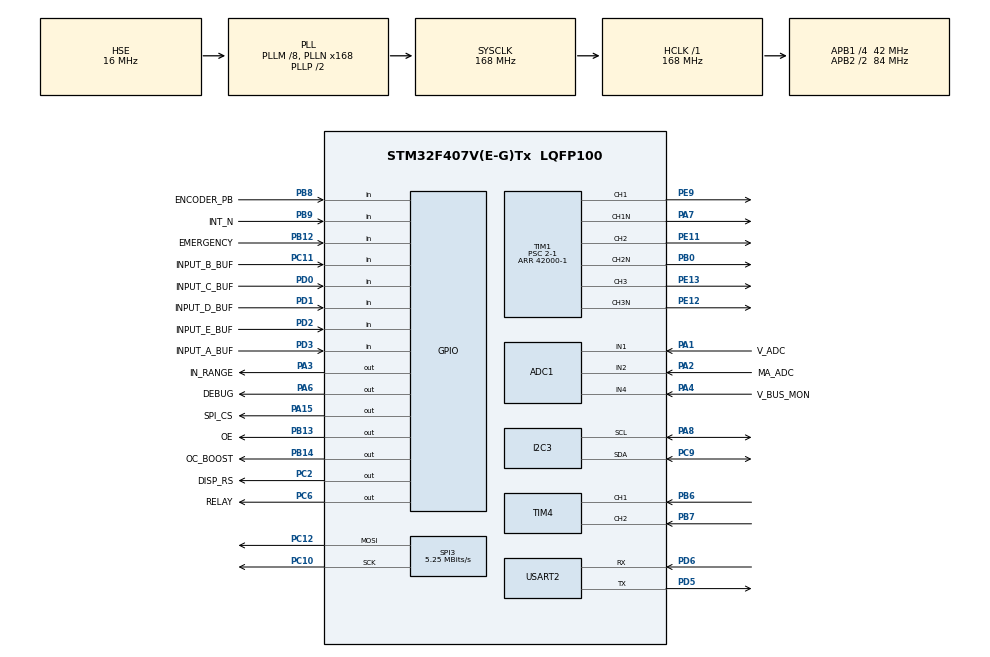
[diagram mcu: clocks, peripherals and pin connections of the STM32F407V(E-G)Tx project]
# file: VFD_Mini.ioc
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ADC1.Channel-0\#ChannelRegularConversion=ADC_CHANNEL_1
ADC1.Channel-1\#ChannelRegularConversion=ADC_CHANNEL_2
ADC1.Channel-2\#ChannelRegularConversion=ADC_CHANNEL_VREFINT
ADC1.Channel-3\#ChannelRegularConversion=ADC_CHANNEL_4
ADC1.ClockPrescaler=ADC_CLOCK_SYNC_PCLK_DIV8
ADC1.ContinuousConvMode=DISABLE
ADC1.DMAContinuousRequests=ENABLE
ADC1.EOCSelection=ADC_EOC_SEQ_CONV
ADC1.ExternalTrigConv=ADC_EXTERNALTRIGCONV_T2_TRGO
ADC1.InjNumberOfConversion=0
ADC1.NbrOfConversion=4
ADC1.NbrOfConversionFlag=1
ADC1.Rank-0\#ChannelRegularConversion=1
ADC1.Rank-1\#ChannelRegularConversion=2
ADC1.Rank-2\#ChannelRegularConversion=3
ADC1.Rank-3\#ChannelRegularConversion=4
ADC1.SamplingTime-0\#ChannelRegularConversion=ADC_SAMPLETIME_28CYCLES
ADC1.SamplingTime-1\#ChannelRegularConversion=ADC_SAMPLETIME_28CYCLES
ADC1.SamplingTime-2\#ChannelRegularConversion=ADC_SAMPLETIME_28CYCLES
ADC1.SamplingTime-3\#ChannelRegularConversion=ADC_SAMPLETIME_28CYCLES
ADC1.master=1
Dma.ADC1.0.Direction=DMA_PERIPH_TO_MEMORY
Dma.ADC1.0.FIFOMode=DMA_FIFOMODE_DISABLE
Dma.ADC1.0.Instance=DMA2_Stream0
Dma.ADC1.0.MemDataAlignment=DMA_MDATAALIGN_HALFWORD
Dma.ADC1.0.MemInc=DMA_MINC_ENABLE
Dma.ADC1.0.Mode=DMA_CIRCULAR
Dma.ADC1.0.PeriphDataAlignment=DMA_PDATAALIGN_HALFWORD
Dma.ADC1.0.PeriphInc=DMA_PINC_DISABLE
Dma.ADC1.0.Priority=DMA_PRIORITY_LOW
Dma.Request0=ADC1
I2C3.I2C_Mode=I2C_Fast
IWDG.Prescaler=IWDG_PRESCALER_64
IWDG.Reload=499
Mcu.Family=STM32F4
Mcu.Name=STM32F407V(E-G)Tx
Mcu.Package=LQFP100
NVIC.ADC_IRQn=true\:0\:0\:false\:false\:true\:true\:true\:true
NVIC.DMA2_Stream0_IRQn=true\:0\:0\:false\:false\:true\:false\:true\:true
NVIC.PriorityGroup=NVIC_PRIORITYGROUP_4
NVIC.TIM8_TRG_COM_TIM14_IRQn=true\:0\:0\:false\:false\:true\:true\:true\:true
PA1.GPIO_Label=V_ADC
PA1.Signal=ADCx_IN1
PA13.Mode=Trace_Asynchronous_SW
PA13.Signal=SYS_JTMS-SWDIO
PA14.Mode=Trace_Asynchronous_SW
PA14.Signal=SYS_JTCK-SWCLK
PA15.GPIO_Label=SPI_CS
PA15.Signal=GPIO_Output
PA2.GPIO_Label=MA_ADC
PA2.Signal=ADCx_IN2
PA3.GPIO_Label=IN_RANGE
PA3.Signal=GPIO_Output
PA4.GPIO_Label=V_BUS_MON
PA4.Signal=ADCx_IN4
PA6.GPIO_Label=DEBUG
PA6.Signal=GPIO_Output
PA7.Mode=PWM Generation1 CH1 CH1N
PA7.Signal=TIM1_CH1N
PA8.Mode=I2C
PA8.Signal=I2C3_SCL
PB0.Mode=PWM Generation2 CH2 CH2N
PB0.Signal=TIM1_CH2N
PB12.GPIO_Label=EMERGENCY
PB12.Signal=GPIO_Input
PB13.GPIO_Label=OE
PB13.Signal=GPIO_Output
PB14.GPIO_Label=OC_BOOST
PB14.Signal=GPIO_Output
PB3.Mode=Trace_Asynchronous_SW
PB3.Signal=SYS_JTDO-SWO
PB6.Signal=S_TIM4_CH1
PB7.Signal=S_TIM4_CH2
PB8.GPIO_Label=ENCODER_PB
PB8.Signal=GPIO_Input
PB9.GPIO_Label=INT_N
PB9.Signal=GPIO_Input
PC10.Mode=TX_Only_Simplex_Unidirect_Master
PC10.Signal=SPI3_SCK
PC11.GPIO_Label=INPUT_B_BUF
PC11.Signal=GPIO_Input
PC12.Mode=TX_Only_Simplex_Unidirect_Master
PC12.Signal=SPI3_MOSI
PC2.GPIO_Label=DISP_RS
PC2.Signal=GPIO_Output
PC6.GPIO_Label=RELAY
PC6.Signal=GPIO_Output
PC9.Mode=I2C
PC9.Signal=I2C3_SDA
PD0.GPIO_Label=INPUT_C_BUF
PD0.Signal=GPIO_Input
PD1.GPIO_Label=INPUT_D_BUF
PD1.Signal=GPIO_Input
PD2.GPIO_Label=INPUT_E_BUF
PD2.Signal=GPIO_Input
PD3.GPIO_Label=INPUT_A_BUF
PD3.Signal=GPIO_Input
PD5.Mode=Asynchronous
PD5.Signal=USART2_TX
PD6.Mode=Asynchronous
PD6.Signal=USART2_RX
PE11.Signal=S_TIM1_CH2
PE12.Mode=PWM Generation3 CH3 CH3N
PE12.Signal=TIM1_CH3N
PE13.Signal=S_TIM1_CH3
PE9.Signal=S_TIM1_CH1
PH0-OSC_IN.Mode=HSE-External-Oscillator
PH0-OSC_IN.Signal=RCC_OSC_IN
PH1-OSC_OUT.Mode=HSE-External-Oscillator
PH1-OSC_OUT.Signal=RCC_OSC_OUT
ProjectManager.HeapSize=0x200
ProjectManager.StackSize=0x400
ProjectManager.TargetToolchain=STM32CubeIDE
RCC.48MHZClocksFreq_Value=84000000
RCC.AHBFreq_Value=168000000
RCC.APB1CLKDivider=RCC_HCLK_DIV4
RCC.APB1Freq_Value=42000000
RCC.APB1TimFreq_Value=84000000
RCC.APB2CLKDivider=RCC_HCLK_DIV2
RCC.APB2Freq_Value=84000000
RCC.APB2TimFreq_Value=168000000
RCC.CortexFreq_Value=168000000
RCC.HCLKFreq_Value=168000000
RCC.HSE_VALUE=16000000
RCC.HSI_VALUE=16000000
RCC.LSE_VALUE=32768
RCC.PLLM=8
RCC.PLLN=168
RCC.PLLSourceVirtual=RCC_PLLSOURCE_HSE
RCC.SYSCLKFreq_VALUE=168000000
RCC.SYSCLKSource=RCC_SYSCLKSOURCE_PLLCLK
RCC.VCOOutputFreq_Value=336000000
SH.ADCx_IN1.0=ADC1_IN1,IN1
SH.ADCx_IN2.0=ADC1_IN2,IN2
SH.ADCx_IN4.0=ADC1_IN4,IN4
SH.S_TIM1_CH1.0=TIM1_CH1,PWM Generation1 CH1 CH1N
SH.S_TIM1_CH2.0=TIM1_CH2,PWM Generation2 CH2 CH2N
SH.S_TIM1_CH3.0=TIM1_CH3,PWM Generation3 CH3 CH3N
SH.S_TIM4_CH1.0=TIM4_CH1,Encoder_Interface
SH.S_TIM4_CH2.0=TIM4_CH2,Encoder_Interface
SPI3.BaudRatePrescaler=SPI_BAUDRATEPRESCALER_8
SPI3.CalculateBaudRate=5.25 MBits/s
SPI3.Direction=SPI_DIRECTION_2LINES
SPI3.Mode=SPI_MODE_MASTER
SPI3.VirtualType=VM_MASTER
TIM1.Channel-PWM\ Generation1\ CH1\ CH1N=TIM_CHANNEL_1
TIM1.Channel-PWM\ Generation2\ CH2\ CH2N=TIM_CHANNEL_2
TIM1.Channel-PWM\ Generation3\ CH3\ CH3N=TIM_CHANNEL_3
TIM1.DeadTime=232
TIM1.OCNPolarity_1=TIM_OCNPOLARITY_LOW
TIM1.OCNPolarity_2=TIM_OCNPOLARITY_LOW
TIM1.OCNPolarity_3=TIM_OCNPOLARITY_LOW
TIM1.Period=42000-1
TIM1.Prescaler=2-1
TIM12.ClockDivision=TIM_CLOCKDIVISION_DIV4
TIM12.Period=50
TIM12.Prescaler=42000-1
TIM14.Period=2000-1
TIM14.Prescaler=168-1
TIM2.AutoReloadPreload=TIM_AUTORELOAD_PRELOAD_ENABLE
TIM2.Period=100-1
TIM2.Prescaler=168-1
TIM2.TIM_MasterOutputTrigger=TIM_TRGO_UPDATE
TIM4.ClockDivision=TIM_CLOCKDIVISION_DIV2
TIM4.EncoderMode=TIM_ENCODERMODE_TI1
USART2.VirtualMode=VM_ASYNC
VP_ADC1_Vref_Input.Mode=IN-Vrefint
VP_IWDG_VS_IWDG.Mode=IWDG_Activate
VP_TIM12_VS_ClockSourceINT.Mode=Internal
VP_TIM12_VS_OPM.Mode=OPM_bit
VP_TIM14_VS_ClockSourceINT.Mode=Enable_Timer
VP_TIM1_VS_ClockSourceINT.Mode=Internal
VP_TIM2_VS_ClockSourceINT.Mode=Internal
board=custom

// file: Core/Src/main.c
/* USER CODE BEGIN Header */
/**
 ******************************************************************************
 * @file           	: main.c
 * @brief          	: Main program body
 * @Author			: Michael Adam
 * @E-Mail			: michael.adam4@proton.me
 ******************************************************************************
 * @attention
 *
 * Copyright (c) 2025 STMicroelectronics.
 * All rights reserved.
 *
 * This software is licensed under terms that can be found in the LICENSE file
 * in the root directory of this software component.
 * If no LICENSE file comes with this software, it is provided AS-IS.
 *
 ******************************************************************************
 */
/* USER CODE END Header */
#include "main.h"

/* USER CODE BEGIN Includes */
#include "main2.h"
#include "vfd.h"

/* USER CODE END Includes */

ADC_HandleTypeDef hadc1;
DMA_HandleTypeDef hdma_adc1;

I2C_HandleTypeDef hi2c3;

IWDG_HandleTypeDef hiwdg;

SPI_HandleTypeDef hspi3;

TIM_HandleTypeDef htim1;
TIM_HandleTypeDef htim2;
TIM_HandleTypeDef htim4;
TIM_HandleTypeDef htim12;
TIM_HandleTypeDef htim14;

UART_HandleTypeDef huart2;

void SystemClock_Config(void);
static void MX_GPIO_Init(void);
static void MX_DMA_Init(void);
static void MX_ADC1_Init(void);
static void MX_TIM1_Init(void);
static void MX_I2C3_Init(void);
static void MX_TIM2_Init(void);
static void MX_SPI3_Init(void);
static void MX_USART2_UART_Init(void);
static void MX_TIM12_Init(void);
static void MX_IWDG_Init(void);
static void MX_TIM14_Init(void);
static void MX_TIM4_Init(void);

int main(void)
{

  /* MCU Configuration--------------------------------------------------------*/

  /* Reset of all peripherals, Initializes the Flash interface and the Systick. */
  HAL_Init();

  /* Configure the system clock */
  SystemClock_Config();

  /* Initialize all configured peripherals */
  MX_GPIO_Init();
  MX_DMA_Init();
  MX_ADC1_Init();
  MX_TIM1_Init();
  MX_I2C3_Init();
  MX_TIM2_Init();
  MX_SPI3_Init();
  MX_USART2_UART_Init();
  MX_TIM12_Init();
  MX_IWDG_Init();
  MX_TIM14_Init();
  MX_TIM4_Init();
  /* USER CODE BEGIN 2 */
	Init();

	Loop();
  /* USER CODE END 2 */

  /* Infinite loop */
	while (1)
	{

	}
}

void SystemClock_Config(void)
{
  RCC_OscInitTypeDef RCC_OscInitStruct = {0};
  RCC_ClkInitTypeDef RCC_ClkInitStruct = {0};

  /** Configure the main internal regulator output voltage
  */
  __HAL_RCC_PWR_CLK_ENABLE();
  __HAL_PWR_VOLTAGESCALING_CONFIG(PWR_REGULATOR_VOLTAGE_SCALE1);

  /** Initializes the RCC Oscillators according to the specified parameters
  * in the RCC_OscInitTypeDef structure.
  */
  RCC_OscInitStruct.OscillatorType = RCC_OSCILLATORTYPE_LSI|RCC_OSCILLATORTYPE_HSE;
  RCC_OscInitStruct.HSEState = RCC_HSE_ON;
  RCC_OscInitStruct.LSIState = RCC_LSI_ON;
  RCC_OscInitStruct.PLL.PLLState = RCC_PLL_ON;
  RCC_OscInitStruct.PLL.PLLSource = RCC_PLLSOURCE_HSE;
  RCC_OscInitStruct.PLL.PLLM = 8;
  RCC_OscInitStruct.PLL.PLLN = 168;
  RCC_OscInitStruct.PLL.PLLP = RCC_PLLP_DIV2;
  RCC_OscInitStruct.PLL.PLLQ = 4;
  if (HAL_RCC_OscConfig(&RCC_OscInitStruct) != HAL_OK)
  {
    Error_Handler();
  }

  /** Initializes the CPU, AHB and APB buses clocks
  */
  RCC_ClkInitStruct.ClockType = RCC_CLOCKTYPE_HCLK|RCC_CLOCKTYPE_SYSCLK
                              |RCC_CLOCKTYPE_PCLK1|RCC_CLOCKTYPE_PCLK2;
  RCC_ClkInitStruct.SYSCLKSource = RCC_SYSCLKSOURCE_PLLCLK;
  RCC_ClkInitStruct.AHBCLKDivider = RCC_SYSCLK_DIV1;
  RCC_ClkInitStruct.APB1CLKDivider = RCC_HCLK_DIV4;
  RCC_ClkInitStruct.APB2CLKDivider = RCC_HCLK_DIV2;

  if (HAL_RCC_ClockConfig(&RCC_ClkInitStruct, FLASH_LATENCY_5) != HAL_OK)
  {
    Error_Handler();
  }
}

static void MX_ADC1_Init(void)
{

  ADC_ChannelConfTypeDef sConfig = {0};

  /** Configure the global features of the ADC (Clock, Resolution, Data Alignment and number of conversion)
  */
  hadc1.Instance = ADC1;
  hadc1.Init.ClockPrescaler = ADC_CLOCK_SYNC_PCLK_DIV8;
  hadc1.Init.Resolution = ADC_RESOLUTION_12B;
  hadc1.Init.ScanConvMode = ENABLE;
  hadc1.Init.ContinuousConvMode = DISABLE;
  hadc1.Init.DiscontinuousConvMode = DISABLE;
  hadc1.Init.ExternalTrigConvEdge = ADC_EXTERNALTRIGCONVEDGE_RISING;
  hadc1.Init.ExternalTrigConv = ADC_EXTERNALTRIGCONV_T2_TRGO;
  hadc1.Init.DataAlign = ADC_DATAALIGN_RIGHT;
  hadc1.Init.NbrOfConversion = 4;
  hadc1.Init.DMAContinuousRequests = ENABLE;
  hadc1.Init.EOCSelection = ADC_EOC_SEQ_CONV;
  if (HAL_ADC_Init(&hadc1) != HAL_OK)
  {
    Error_Handler();
  }

  /** Configure for the selected ADC regular channel its corresponding rank in the sequencer and its sample time.
  */
  sConfig.Channel = ADC_CHANNEL_1;
  sConfig.Rank = 1;
  sConfig.SamplingTime = ADC_SAMPLETIME_28CYCLES;
  if (HAL_ADC_ConfigChannel(&hadc1, &sConfig) != HAL_OK)
  {
    Error_Handler();
  }

  /** Configure for the selected ADC regular channel its corresponding rank in the sequencer and its sample time.
  */
  sConfig.Channel = ADC_CHANNEL_2;
  sConfig.Rank = 2;
  if (HAL_ADC_ConfigChannel(&hadc1, &sConfig) != HAL_OK)
  {
    Error_Handler();
  }

  /** Configure for the selected ADC regular channel its corresponding rank in the sequencer and its sample time.
  */
  sConfig.Channel = ADC_CHANNEL_VREFINT;
  sConfig.Rank = 3;
  if (HAL_ADC_ConfigChannel(&hadc1, &sConfig) != HAL_OK)
  {
    Error_Handler();
  }

  /** Configure for the selected ADC regular channel its corresponding rank in the sequencer and its sample time.
  */
  sConfig.Channel = ADC_CHANNEL_4;
  sConfig.Rank = 4;
  if (HAL_ADC_ConfigChannel(&hadc1, &sConfig) != HAL_OK)
  {
    Error_Handler();
  }

}

static void MX_I2C3_Init(void)
{

  hi2c3.Instance = I2C3;
  hi2c3.Init.ClockSpeed = 400000;
  hi2c3.Init.DutyCycle = I2C_DUTYCYCLE_2;
  hi2c3.Init.OwnAddress1 = 0;
  hi2c3.Init.AddressingMode = I2C_ADDRESSINGMODE_7BIT;
  hi2c3.Init.DualAddressMode = I2C_DUALADDRESS_DISABLE;
  hi2c3.Init.OwnAddress2 = 0;
  hi2c3.Init.GeneralCallMode = I2C_GENERALCALL_DISABLE;
  hi2c3.Init.NoStretchMode = I2C_NOSTRETCH_DISABLE;
  if (HAL_I2C_Init(&hi2c3) != HAL_OK)
  {
    Error_Handler();
  }

}

static void MX_IWDG_Init(void)
{

  hiwdg.Instance = IWDG;
  hiwdg.Init.Prescaler = IWDG_PRESCALER_64;
  hiwdg.Init.Reload = 499;
  if (HAL_IWDG_Init(&hiwdg) != HAL_OK)
  {
    Error_Handler();
  }

}

static void MX_SPI3_Init(void)
{

  /* SPI3 parameter configuration*/
  hspi3.Instance = SPI3;
  hspi3.Init.Mode = SPI_MODE_MASTER;
  hspi3.Init.Direction = SPI_DIRECTION_2LINES;
  hspi3.Init.DataSize = SPI_DATASIZE_8BIT;
  hspi3.Init.CLKPolarity = SPI_POLARITY_LOW;
  hspi3.Init.CLKPhase = SPI_PHASE_1EDGE;
  hspi3.Init.NSS = SPI_NSS_SOFT;
  hspi3.Init.BaudRatePrescaler = SPI_BAUDRATEPRESCALER_8;
  hspi3.Init.FirstBit = SPI_FIRSTBIT_MSB;
  hspi3.Init.TIMode = SPI_TIMODE_DISABLE;
  hspi3.Init.CRCCalculation = SPI_CRCCALCULATION_DISABLE;
  hspi3.Init.CRCPolynomial = 10;
  if (HAL_SPI_Init(&hspi3) != HAL_OK)
  {
    Error_Handler();
  }

}

static void MX_TIM1_Init(void)
{

  TIM_ClockConfigTypeDef sClockSourceConfig = {0};
  TIM_MasterConfigTypeDef sMasterConfig = {0};
  TIM_OC_InitTypeDef sConfigOC = {0};
  TIM_BreakDeadTimeConfigTypeDef sBreakDeadTimeConfig = {0};

  htim1.Instance = TIM1;
  htim1.Init.Prescaler = 2-1;
  htim1.Init.CounterMode = TIM_COUNTERMODE_UP;
  htim1.Init.Period = 42000-1;
  htim1.Init.ClockDivision = TIM_CLOCKDIVISION_DIV1;
  htim1.Init.RepetitionCounter = 0;
  htim1.Init.AutoReloadPreload = TIM_AUTORELOAD_PRELOAD_DISABLE;
  if (HAL_TIM_Base_Init(&htim1) != HAL_OK)
  {
    Error_Handler();
  }
  sClockSourceConfig.ClockSource = TIM_CLOCKSOURCE_INTERNAL;
  if (HAL_TIM_ConfigClockSource(&htim1, &sClockSourceConfig) != HAL_OK)
  {
    Error_Handler();
  }
  if (HAL_TIM_PWM_Init(&htim1) != HAL_OK)
  {
    Error_Handler();
  }
  sMasterConfig.MasterOutputTrigger = TIM_TRGO_RESET;
  sMasterConfig.MasterSlaveMode = TIM_MASTERSLAVEMODE_DISABLE;
  if (HAL_TIMEx_MasterConfigSynchronization(&htim1, &sMasterConfig) != HAL_OK)
  {
    Error_Handler();
  }
  sConfigOC.OCMode = TIM_OCMODE_PWM1;
  sConfigOC.Pulse = 0;
  sConfigOC.OCPolarity = TIM_OCPOLARITY_HIGH;
  sConfigOC.OCNPolarity = TIM_OCNPOLARITY_LOW;
  sConfigOC.OCFastMode = TIM_OCFAST_DISABLE;
  sConfigOC.OCIdleState = TIM_OCIDLESTATE_RESET;
  sConfigOC.OCNIdleState = TIM_OCNIDLESTATE_RESET;
  if (HAL_TIM_PWM_ConfigChannel(&htim1, &sConfigOC, TIM_CHANNEL_1) != HAL_OK)
  {
    Error_Handler();
  }
  if (HAL_TIM_PWM_ConfigChannel(&htim1, &sConfigOC, TIM_CHANNEL_2) != HAL_OK)
  {
    Error_Handler();
  }
  if (HAL_TIM_PWM_ConfigChannel(&htim1, &sConfigOC, TIM_CHANNEL_3) != HAL_OK)
  {
    Error_Handler();
  }
  sBreakDeadTimeConfig.OffStateRunMode = TIM_OSSR_DISABLE;
  sBreakDeadTimeConfig.OffStateIDLEMode = TIM_OSSI_DISABLE;
  sBreakDeadTimeConfig.LockLevel = TIM_LOCKLEVEL_OFF;
  sBreakDeadTimeConfig.DeadTime = 232;
  sBreakDeadTimeConfig.BreakState = TIM_BREAK_DISABLE;
  sBreakDeadTimeConfig.BreakPolarity = TIM_BREAKPOLARITY_HIGH;
  sBreakDeadTimeConfig.AutomaticOutput = TIM_AUTOMATICOUTPUT_DISABLE;
  if (HAL_TIMEx_ConfigBreakDeadTime(&htim1, &sBreakDeadTimeConfig) != HAL_OK)
  {
    Error_Handler();
  }
  HAL_TIM_MspPostInit(&htim1);

}

static void MX_TIM2_Init(void)
{

  TIM_ClockConfigTypeDef sClockSourceConfig = {0};
  TIM_MasterConfigTypeDef sMasterConfig = {0};

  htim2.Instance = TIM2;
  htim2.Init.Prescaler = 168-1;
  htim2.Init.CounterMode = TIM_COUNTERMODE_UP;
  htim2.Init.Period = 100-1;
  htim2.Init.ClockDivision = TIM_CLOCKDIVISION_DIV1;
  htim2.Init.AutoReloadPreload = TIM_AUTORELOAD_PRELOAD_ENABLE;
  if (HAL_TIM_Base_Init(&htim2) != HAL_OK)
  {
    Error_Handler();
  }
  sClockSourceConfig.ClockSource = TIM_CLOCKSOURCE_INTERNAL;
  if (HAL_TIM_ConfigClockSource(&htim2, &sClockSourceConfig) != HAL_OK)
  {
    Error_Handler();
  }
  sMasterConfig.MasterOutputTrigger = TIM_TRGO_UPDATE;
  sMasterConfig.MasterSlaveMode = TIM_MASTERSLAVEMODE_DISABLE;
  if (HAL_TIMEx_MasterConfigSynchronization(&htim2, &sMasterConfig) != HAL_OK)
  {
    Error_Handler();
  }

}

static void MX_TIM4_Init(void)
{

  TIM_Encoder_InitTypeDef sConfig = {0};
  TIM_MasterConfigTypeDef sMasterConfig = {0};

  htim4.Instance = TIM4;
  htim4.Init.Prescaler = 0;
  htim4.Init.CounterMode = TIM_COUNTERMODE_UP;
  htim4.Init.Period = 65535;
  htim4.Init.ClockDivision = TIM_CLOCKDIVISION_DIV2;
  htim4.Init.AutoReloadPreload = TIM_AUTORELOAD_PRELOAD_DISABLE;
  sConfig.EncoderMode = TIM_ENCODERMODE_TI1;
  sConfig.IC1Polarity = TIM_ICPOLARITY_RISING;
  sConfig.IC1Selection = TIM_ICSELECTION_DIRECTTI;
  sConfig.IC1Prescaler = TIM_ICPSC_DIV1;
  sConfig.IC1Filter = 0;
  sConfig.IC2Polarity = TIM_ICPOLARITY_RISING;
  sConfig.IC2Selection = TIM_ICSELECTION_DIRECTTI;
  sConfig.IC2Prescaler = TIM_ICPSC_DIV1;
  sConfig.IC2Filter = 0;
  if (HAL_TIM_Encoder_Init(&htim4, &sConfig) != HAL_OK)
  {
    Error_Handler();
  }
  sMasterConfig.MasterOutputTrigger = TIM_TRGO_RESET;
  sMasterConfig.MasterSlaveMode = TIM_MASTERSLAVEMODE_DISABLE;
  if (HAL_TIMEx_MasterConfigSynchronization(&htim4, &sMasterConfig) != HAL_OK)
  {
    Error_Handler();
  }

}

static void MX_TIM12_Init(void)
{

  TIM_ClockConfigTypeDef sClockSourceConfig = {0};

  htim12.Instance = TIM12;
  htim12.Init.Prescaler = 42000-1;
  htim12.Init.CounterMode = TIM_COUNTERMODE_UP;
  htim12.Init.Period = 50;
  htim12.Init.ClockDivision = TIM_CLOCKDIVISION_DIV4;
  htim12.Init.AutoReloadPreload = TIM_AUTORELOAD_PRELOAD_DISABLE;
  if (HAL_TIM_Base_Init(&htim12) != HAL_OK)
  {
    Error_Handler();
  }
  sClockSourceConfig.ClockSource = TIM_CLOCKSOURCE_INTERNAL;
  if (HAL_TIM_ConfigClockSource(&htim12, &sClockSourceConfig) != HAL_OK)
  {
    Error_Handler();
  }
  if (HAL_TIM_OnePulse_Init(&htim12, TIM_OPMODE_SINGLE) != HAL_OK)
  {
    Error_Handler();
  }

}

static void MX_TIM14_Init(void)
{

  htim14.Instance = TIM14;
  htim14.Init.Prescaler = 168-1;
  htim14.Init.CounterMode = TIM_COUNTERMODE_UP;
  htim14.Init.Period = 2000-1;
  htim14.Init.ClockDivision = TIM_CLOCKDIVISION_DIV1;
  htim14.Init.AutoReloadPreload = TIM_AUTORELOAD_PRELOAD_DISABLE;
  if (HAL_TIM_Base_Init(&htim14) != HAL_OK)
  {
    Error_Handler();
  }

}

static void MX_USART2_UART_Init(void)
{

  huart2.Instance = USART2;
  huart2.Init.BaudRate = 115200;
  huart2.Init.WordLength = UART_WORDLENGTH_8B;
  huart2.Init.StopBits = UART_STOPBITS_1;
  huart2.Init.Parity = UART_PARITY_NONE;
  huart2.Init.Mode = UART_MODE_TX_RX;
  huart2.Init.HwFlowCtl = UART_HWCONTROL_NONE;
  huart2.Init.OverSampling = UART_OVERSAMPLING_16;
  if (HAL_UART_Init(&huart2) != HAL_OK)
  {
    Error_Handler();
  }

}

static void MX_DMA_Init(void)
{

  /* DMA controller clock enable */
  __HAL_RCC_DMA2_CLK_ENABLE();

  /* DMA interrupt init */
  /* DMA2_Stream0_IRQn interrupt configuration */
  HAL_NVIC_SetPriority(DMA2_Stream0_IRQn, 0, 0);
  HAL_NVIC_EnableIRQ(DMA2_Stream0_IRQn);

}

static void MX_GPIO_Init(void)
{
  GPIO_InitTypeDef GPIO_InitStruct = {0};

  /* GPIO Ports Clock Enable */
  __HAL_RCC_GPIOH_CLK_ENABLE();
  __HAL_RCC_GPIOC_CLK_ENABLE();
  __HAL_RCC_GPIOA_CLK_ENABLE();
  __HAL_RCC_GPIOB_CLK_ENABLE();
  __HAL_RCC_GPIOE_CLK_ENABLE();
  __HAL_RCC_GPIOD_CLK_ENABLE();

  /*Configure GPIO pin Output Level */
  HAL_GPIO_WritePin(GPIOC, DISP_RS_Pin|RELAY_Pin, GPIO_PIN_RESET);

  /*Configure GPIO pin Output Level */
  HAL_GPIO_WritePin(GPIOA, IN_RANGE_Pin|DEBUG_Pin|SPI_CS_Pin, GPIO_PIN_RESET);

  /*Configure GPIO pin Output Level */
  HAL_GPIO_WritePin(GPIOB, OE_Pin|OC_BOOST_Pin, GPIO_PIN_RESET);

  /*Configure GPIO pins : DISP_RS_Pin RELAY_Pin */
  GPIO_InitStruct.Pin = DISP_RS_Pin|RELAY_Pin;
  GPIO_InitStruct.Mode = GPIO_MODE_OUTPUT_PP;
  GPIO_InitStruct.Pull = GPIO_NOPULL;
  GPIO_InitStruct.Speed = GPIO_SPEED_FREQ_LOW;
  HAL_GPIO_Init(GPIOC, &GPIO_InitStruct);

  /*Configure GPIO pins : IN_RANGE_Pin DEBUG_Pin SPI_CS_Pin */
  GPIO_InitStruct.Pin = IN_RANGE_Pin|DEBUG_Pin|SPI_CS_Pin;
  GPIO_InitStruct.Mode = GPIO_MODE_OUTPUT_PP;
  GPIO_InitStruct.Pull = GPIO_NOPULL;
  GPIO_InitStruct.Speed = GPIO_SPEED_FREQ_LOW;
  HAL_GPIO_Init(GPIOA, &GPIO_InitStruct);

  /*Configure GPIO pins : EMERGENCY_Pin ENCODER_PB_Pin INT_N_Pin */
  GPIO_InitStruct.Pin = EMERGENCY_Pin|ENCODER_PB_Pin|INT_N_Pin;
  GPIO_InitStruct.Mode = GPIO_MODE_INPUT;
  GPIO_InitStruct.Pull = GPIO_NOPULL;
  HAL_GPIO_Init(GPIOB, &GPIO_InitStruct);

  /*Configure GPIO pins : OE_Pin OC_BOOST_Pin */
  GPIO_InitStruct.Pin = OE_Pin|OC_BOOST_Pin;
  GPIO_InitStruct.Mode = GPIO_MODE_OUTPUT_PP;
  GPIO_InitStruct.Pull = GPIO_NOPULL;
  GPIO_InitStruct.Speed = GPIO_SPEED_FREQ_LOW;
  HAL_GPIO_Init(GPIOB, &GPIO_InitStruct);

  /*Configure GPIO pin : INPUT_B_BUF_Pin */
  GPIO_InitStruct.Pin = INPUT_B_BUF_Pin;
  GPIO_InitStruct.Mode = GPIO_MODE_INPUT;
  GPIO_InitStruct.Pull = GPIO_NOPULL;
  HAL_GPIO_Init(INPUT_B_BUF_GPIO_Port, &GPIO_InitStruct);

  /*Configure GPIO pins : INPUT_C_BUF_Pin INPUT_D_BUF_Pin INPUT_E_BUF_Pin INPUT_A_BUF_Pin */
  GPIO_InitStruct.Pin = INPUT_C_BUF_Pin|INPUT_D_BUF_Pin|INPUT_E_BUF_Pin|INPUT_A_BUF_Pin;
  GPIO_InitStruct.Mode = GPIO_MODE_INPUT;
  GPIO_InitStruct.Pull = GPIO_NOPULL;
  HAL_GPIO_Init(GPIOD, &GPIO_InitStruct);

}

void Error_Handler(void)
{
	__disable_irq();
	while (1)
	{
	}
}
